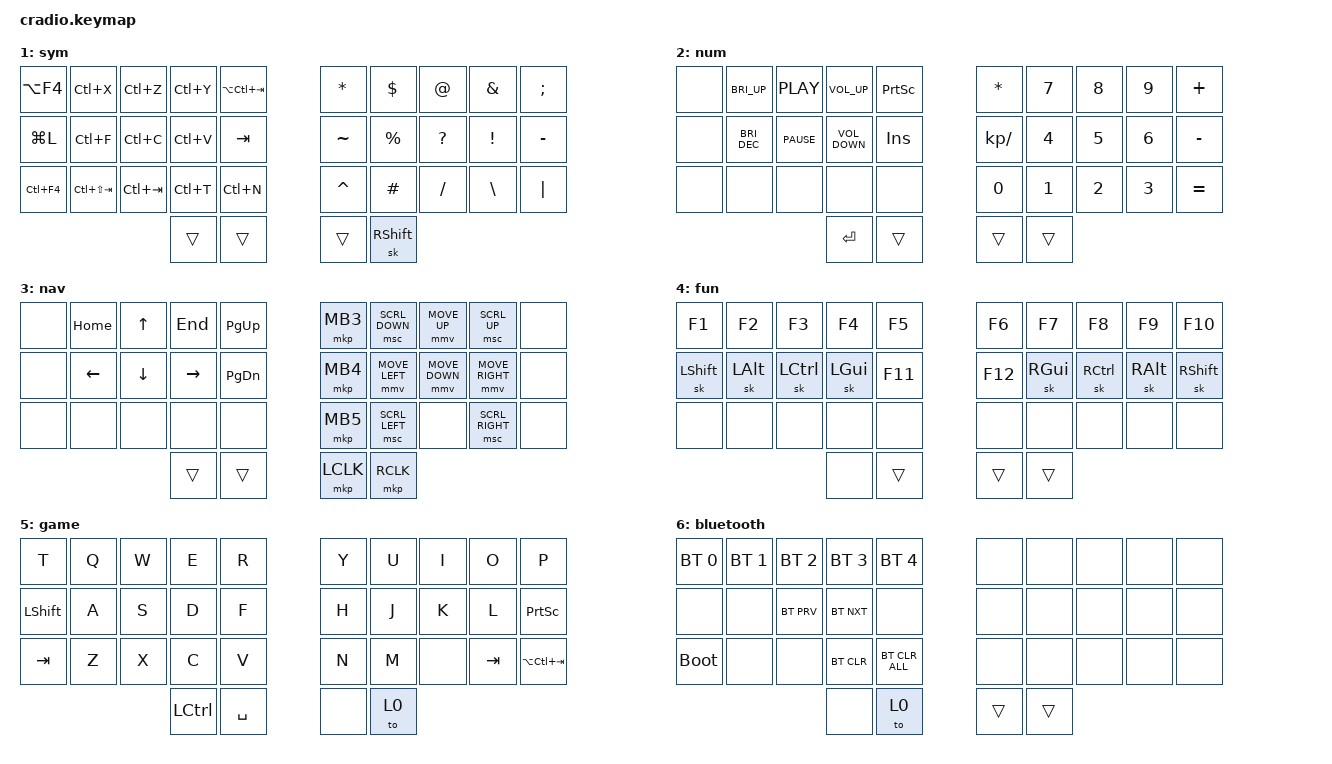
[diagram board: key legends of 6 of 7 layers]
#include <behaviors.dtsi>
#include <dt-bindings/zmk/bt.h>
#include <dt-bindings/zmk/keys.h>

#define ZMK_POINTING_DEFAULT_MOVE_VAL 1400  // 600, 1200
#define ZMK_MOUSE_DEFAULT_SCRL_VAL 20    // 10

#include <dt-bindings/zmk/pointing.h>

#define HRML(k1,k2,k3,k4) &ht LSHFT k1  &ht LALT k2  &ht LCTRL k3  &ht LGUI k4
#define HRMR(k1,k2,k3,k4) &ht RGUI k1  &ht RCTRL k2  &ht RALT k3  &ht RSHFT k4

&lt {
    tapping-term-ms = <250>;
};

&sk {
    release-after-ms = <2000>;
    quick-release;
    /delete-property/ ignore-modifiers;
};

/ {

    behaviors {
        mmv {
            acceleration-exponent = <1>;      // 1
            time-to-max-speed-ms = <40>;    // 40
            delay-ms = <0>;                   // 0
        };
    };

    behaviors {
        ht: hold_tap {
            compatible = "zmk,behavior-hold-tap";
            #binding-cells = <2>;
            flavor = "tap-preferred";
            tapping-term-ms = <300>;
            quick-tap-ms = <150>;
            require-prior-idle-ms = <100>;
            bindings = <&kp>, <&kp>;
        };
    };

    behaviors {
         tp_repeat_mo: tp_repeat_mo {
         compatible = "zmk,behavior-hold-tap";
         label = "TP_REPEAT_MO";
         flavor = "tap-preferred";
         #binding-cells = <2>;
         tapping-term-ms = <250>;
         require-prior-idle-ms = <100>;
         bindings = <&mo>, <&key_repeat>;
       };
};

    behaviors {
         magic_shift: magic_shift {
         compatible = "zmk,behavior-hold-tap";
         label = "magic_shift";
         flavor = "tap-preferred";
         #binding-cells = <2>;
         tapping-term-ms = <280>;
         require-prior-idle-ms = <100>;
         bindings = <&mo>, <&sk>;
       };
};

    behaviors {
         layer_enter: layer_enter {
         compatible = "zmk,behavior-hold-tap";
         label = "layer_enter";
         flavor = "tap-preferred";
         #binding-cells = <2>;
         tapping-term-ms = <200>;
         require-prior-idle-ms = <100>;
         bindings = <&mo>, <&kp>;
       };
};

    combos {
        compatible = "zmk,combos";

        esc {
            require-prior-idle-ms = <125>;
            bindings = <&kp ESCAPE>;
            key-positions = <0 1>;
            layers = <0 1 2 3 4 5>;
        };

        caps {
            require-prior-idle-ms = <125>;
            bindings = <&kp CAPS>;
            key-positions = <1 8>;
            layers = <0>;
        };

        cword {
            require-prior-idle-ms = <125>;
            bindings = <&caps_word>;
            key-positions = <2 7>;
            layers = <0>;
        };

        backword {
            require-prior-idle-ms = <125>;
            bindings = <&kp LC(BACKSPACE)>;
            key-positions = <31 32>;
            layers = <0>;
        };

        del {
            require-prior-idle-ms = <125>;
            bindings = <&kp DEL>;
            key-positions = <8 9>;
            layers = <0>;
        };

        bspc {
            require-prior-idle-ms = <125>;
            bindings = <&kp BACKSPACE>;
            key-positions = <26 27>;
            layers = <0>;
        };

        game {
            require-prior-idle-ms = <125>;
            bindings = <&to 5>;
            key-positions = <30 31>;
            layers = <0>;
        };


        lbrac {
            require-prior-idle-ms = <125>;
            bindings = <&kp LEFT_BRACKET>;
            key-positions = <1 11>;
            layers = <0>;
        };

        lpar {
            require-prior-idle-ms = <125>;
            bindings = <&kp LEFT_PARENTHESIS>;
            key-positions = <2 12>;
            layers = <0>;
        };

        lbrace {
            require-prior-idle-ms = <125>;
            bindings = <&kp LEFT_BRACE>;
            key-positions = <3 13>;
            layers = <0>;
        };

        less {
            require-prior-idle-ms = <125>;
            bindings = <&kp LESS_THAN>;
            key-positions = <4 14>;
            layers = <0>;
        };

        great {
            require-prior-idle-ms = <125>;
            bindings = <&kp GREATER_THAN>;
            key-positions = <5 15>;
            layers = <0>;
        };

        rbrace { 
            require-prior-idle-ms = <125>;
            bindings = <&kp RIGHT_BRACE>;
            key-positions = <6 16>;
            layers = <0>;
        };

        rpar {
            require-prior-idle-ms = <125>;
            bindings = <&kp RIGHT_PARENTHESIS>;
            key-positions = <7 17>;
            layers = <0>;
        };

        rbrac {
            require-prior-idle-ms = <125>;
            bindings = <&kp RIGHT_BRACKET>;
            key-positions = <8 18>;
            layers = <0>;
        };

        quote {
            require-prior-idle-ms = <125>;
            bindings = <&kp DOUBLE_QUOTES>;
            key-positions = <7 8>;
            layers = <0>;
        };

        gameEnter {
            require-prior-idle-ms = <125>;
            bindings = <&kp ENTER>;
            key-positions = <30 31>;
            layers = <5>;
        };

        gameG {
            require-prior-idle-ms = <125>;
            bindings = <&kp G>;
            key-positions = <4 14>;
            layers = <5>;
        };

        gameB {
            require-prior-idle-ms = <125>;
            bindings = <&kp B>;
            key-positions = <24 14>;
            layers = <5>;
        };

        bluetooth {
            require-prior-idle-ms = <125>;
            bindings = <&to 6>;
            key-positions = <20 21>;
            layers = <1 2 3>;
        };

        tab {
            require-prior-idle-ms = <125>;
            bindings = <&kp TAB>;
            key-positions = <11 12>;
            layers = <0>;
        };

        altf4 {
            require-prior-idle-ms = <125>;
            bindings = <&kp RA(F4)>;
            key-positions = <8 9>;
            layers = <5>;
        };
    };

    keymap {
        compatible = "zmk,keymap";

        base {
            bindings = <
&kp W  &kp L  &kp Y  &kp P  &kp B          &kp Z        &kp F  &kp O      &kp U      &kp SQT
HRML(C,  R,   S,     T)  &kp G          &kp M       HRMR( N,   E,       I,     A)
&kp Q  &kp J  &kp V  &kp D  &kp K          &kp X        &kp H  &kp SLASH  &kp COMMA  &kp PERIOD
                     &layer_enter 1 ENTER  &lt 3 SPACE    &tp_repeat_mo 2 0  &magic_shift 4 RSHIFT
            >;
        };

        sym {
            bindings = <
&kp LA(F4)  &kp LC(X)  &kp LC(Z)  &kp LC(Y)  &kp LA(LC(TAB))           &kp ASTRK   &kp DOLLAR      &kp AT_SIGN    &kp AMPERSAND     &kp SEMICOLON
&kp LG(L)   &kp LC(F)  &kp LC(C)  &kp LC(V)  &kp TAB                  &kp TILDE   &kp PERCENT     &kp QUESTION   &kp EXCLAMATION   &kp MINUS
&kp LC(F4)  &kp LC(LS(TAB))  &kp LC(TAB)     &kp LC(T)  &kp LC(N)     &kp CARET   &kp HASH        &kp FSLH       &kp BACKSLASH     &kp PIPE
                                 &trans      &trans                    &trans      &sk RSHIFT
            >;
        };

        num {
            bindings = <
&none  &kp C_BRI_UP   &kp C_PLAY       &kp C_VOLUME_UP    &kp PRINTSCREEN    &kp ASTRK      &kp N7        &kp N8        &kp N9        &kp PLUS
&none  &kp C_BRI_DEC  &kp C_PAUSE      &kp C_VOLUME_DOWN  &kp INS            &kp KP_DIVIDE  &kp NUMBER_4  &kp N5        &kp NUMBER_6  &kp MINUS
&none  &none          &none              &none              &none              &kp NUMBER_0   &kp NUMBER_1  &kp NUMBER_2  &kp NUMBER_3  &kp EQUAL
                                       &kp ENTER              &trans             &trans          &trans
            >;
        };

        nav {
            bindings = <
&none   &kp HOME            &kp UP_ARROW  &kp END            &kp PAGE_UP      &mkp MB3      &msc SCRL_DOWN    &mmv MOVE_UP      &msc SCRL_UP       &none
&none   &kp LEFT_ARROW  &kp DOWN_ARROW     &kp RIGHT_ARROW   &kp PAGE_DOWN    &mkp MB4      &mmv MOVE_LEFT    &mmv MOVE_DOWN    &mmv MOVE_RIGHT    &none
&none     &none           &none              &none             &none            &mkp MB5      &msc SCRL_LEFT    &none           &msc SCRL_RIGHT    &none
                                             &trans            &trans           &mkp LCLK     &mkp RCLK
            >;
        };

        fun {
            bindings = <
&kp F1          &kp F2        &kp F3     &kp F4        &kp F5     &kp F6   &kp F7         &kp F8     &kp F9         &kp F10
&sk LEFT_SHIFT  &sk LEFT_ALT  &sk LCTRL  &sk LEFT_GUI  &kp F11    &kp F12  &sk RIGHT_GUI  &sk RCTRL  &sk RIGHT_ALT  &sk RSHIFT
&none           &none         &none      &none         &none      &none    &none          &none      &none          &none
                                         &none         &trans     &trans   &trans
            >;
        };

        game {
            bindings = <
&kp T      &kp Q  &kp W  &kp E      &kp R        &kp Y    &kp U  &kp I  &kp O  &kp P
&kp LSHFT  &kp A  &kp S  &kp D      &kp F        &kp H    &kp J  &kp K  &kp L  &kp PRINTSCREEN
&kp TAB    &kp Z  &kp X  &kp C      &kp V        &kp N    &kp M  &none  &kp TAB  &kp LA(LC(TAB))
                         &kp LCTRL  &kp SPACE    &none  &to 0
            >;
        };

        bluetooth {
            bindings = <
&bt BT_SEL 0  &bt BT_SEL 1  &bt BT_SEL 2  &bt BT_SEL 3  &bt BT_SEL 4      &none   &none   &none  &none  &none
&none         &none         &bt BT_PRV    &bt BT_NXT    &none             &none   &none   &none  &none  &none
&bootloader   &none         &none         &bt BT_CLR    &bt BT_CLR_ALL    &none   &none   &none  &none  &none
                                          &none         &to 0             &trans  &trans
            >;
        };
    };
};
